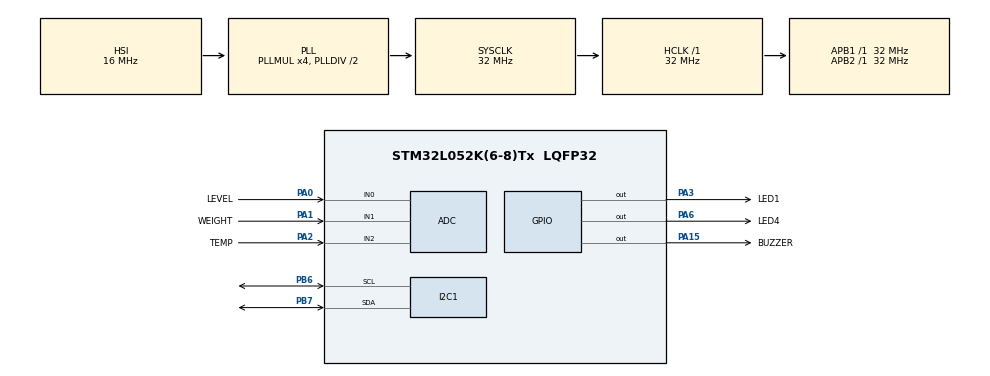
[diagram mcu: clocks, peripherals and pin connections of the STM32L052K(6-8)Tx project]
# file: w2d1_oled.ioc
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ADC.DMAContinuousRequests=ENABLE
ADC.SamplingTime=ADC_SAMPLETIME_160CYCLES_5
Dma.ADC.0.Direction=DMA_PERIPH_TO_MEMORY
Dma.ADC.0.Instance=DMA1_Channel1
Dma.ADC.0.MemDataAlignment=DMA_MDATAALIGN_WORD
Dma.ADC.0.MemInc=DMA_MINC_ENABLE
Dma.ADC.0.Mode=DMA_CIRCULAR
Dma.ADC.0.PeriphDataAlignment=DMA_PDATAALIGN_HALFWORD
Dma.ADC.0.PeriphInc=DMA_PINC_DISABLE
Dma.ADC.0.Priority=DMA_PRIORITY_LOW
Dma.Request0=ADC
I2C1.Timing=0x00707CBB
Mcu.Family=STM32L0
Mcu.Name=STM32L052K(6-8)Tx
Mcu.Package=LQFP32
NVIC.ADC1_COMP_IRQn=true\:0\:0\:false\:false\:true\:true\:true
NVIC.DMA1_Channel1_IRQn=true\:0\:0\:false\:false\:true\:false\:true
PA0.GPIO_Label=LEVEL
PA0.Signal=SharedAnalog_PA0
PA1.GPIO_Label=WEIGHT
PA1.Mode=IN1
PA1.Signal=ADC_IN1
PA13.Mode=Serial_Wire
PA13.Signal=SYS_SWDIO
PA14.Mode=Serial_Wire
PA14.Signal=SYS_SWCLK
PA15.GPIO_Label=BUZZER
PA15.Signal=GPIO_Output
PA2.GPIO_Label=TEMP
PA2.Mode=IN2
PA2.Signal=ADC_IN2
PA3.GPIO_Label=LED1
PA3.Signal=GPIO_Output
PA6.GPIO_Label=LED4
PA6.Signal=GPIO_Output
PB6.Mode=I2C
PB6.Signal=I2C1_SCL
PB7.Mode=I2C
PB7.Signal=I2C1_SDA
ProjectManager.HeapSize=0x200
ProjectManager.StackSize=0x400
ProjectManager.TargetToolchain=STM32CubeIDE
RCC.AHBFreq_Value=32000000
RCC.APB1Freq_Value=32000000
RCC.APB1TimFreq_Value=32000000
RCC.APB2Freq_Value=32000000
RCC.APB2TimFreq_Value=32000000
RCC.HCLKFreq_Value=32000000
RCC.HSI16_VALUE=16000000
RCC.HSI48_VALUE=48000000
RCC.HSI_VALUE=16000000
RCC.LSE_VALUE=32768
RCC.MSI_VALUE=2097000
RCC.PLLMUL=RCC_PLLMUL_4
RCC.SYSCLKFreq_VALUE=32000000
RCC.SYSCLKSource=RCC_SYSCLKSOURCE_PLLCLK
RCC.VCOOutputFreq_Value=64000000
SH.SharedAnalog_PA0.0=GPIO_Analog
SH.SharedAnalog_PA0.1=ADC_IN0,IN0
board=custom

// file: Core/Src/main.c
/* USER CODE BEGIN Header */
/**
 ******************************************************************************
 * @file           : main.c
 * @brief          : Main program body
 ******************************************************************************
 * @attention
 *
 * Copyright (c) 2021 STMicroelectronics.
 * All rights reserved.
 *
 * This software is licensed under terms that can be found in the LICENSE file
 * in the root directory of this software component.
 * If no LICENSE file comes with this software, it is provided AS-IS.
 *
 ******************************************************************************
 */
/* USER CODE END Header */
#include "main.h"

/* USER CODE BEGIN Includes */
#include "App.h"
/* USER CODE END Includes */

ADC_HandleTypeDef hadc;
DMA_HandleTypeDef hdma_adc;

I2C_HandleTypeDef hi2c1;

void SystemClock_Config(void);
static void MX_GPIO_Init(void);
static void MX_I2C1_Init(void);
static void MX_DMA_Init(void);
static void MX_ADC_Init(void);

int main(void)
{

  /* MCU Configuration--------------------------------------------------------*/

  /* Reset of all peripherals, Initializes the Flash interface and the Systick. */
  HAL_Init();

  /* Configure the system clock */
  SystemClock_Config();

  /* Initialize all configured peripherals */
  MX_GPIO_Init();
  MX_I2C1_Init();
  MX_DMA_Init();
  MX_ADC_Init();
  /* USER CODE BEGIN 2 */
  lcd_init(&hi2c1);
  OLED_ShowString(0, 0, "Starting...", 0);
  HAL_Delay(1000);
  OLED_Clear();
  /* USER CODE END 2 */

  /* Infinite loop */
  /* USER CODE BEGIN WHILE */
	while (1) {
		appLoop();
    /* USER CODE END WHILE */

	}
}

void SystemClock_Config(void)
{
  RCC_OscInitTypeDef RCC_OscInitStruct = {0};
  RCC_ClkInitTypeDef RCC_ClkInitStruct = {0};
  RCC_PeriphCLKInitTypeDef PeriphClkInit = {0};

  /** Configure the main internal regulator output voltage
  */
  __HAL_PWR_VOLTAGESCALING_CONFIG(PWR_REGULATOR_VOLTAGE_SCALE1);
  /** Initializes the RCC Oscillators according to the specified parameters
  * in the RCC_OscInitTypeDef structure.
  */
  RCC_OscInitStruct.OscillatorType = RCC_OSCILLATORTYPE_HSI;
  RCC_OscInitStruct.HSIState = RCC_HSI_ON;
  RCC_OscInitStruct.HSICalibrationValue = RCC_HSICALIBRATION_DEFAULT;
  RCC_OscInitStruct.PLL.PLLState = RCC_PLL_ON;
  RCC_OscInitStruct.PLL.PLLSource = RCC_PLLSOURCE_HSI;
  RCC_OscInitStruct.PLL.PLLMUL = RCC_PLLMUL_4;
  RCC_OscInitStruct.PLL.PLLDIV = RCC_PLLDIV_2;
  if (HAL_RCC_OscConfig(&RCC_OscInitStruct) != HAL_OK)
  {
    Error_Handler();
  }
  /** Initializes the CPU, AHB and APB buses clocks
  */
  RCC_ClkInitStruct.ClockType = RCC_CLOCKTYPE_HCLK|RCC_CLOCKTYPE_SYSCLK
                              |RCC_CLOCKTYPE_PCLK1|RCC_CLOCKTYPE_PCLK2;
  RCC_ClkInitStruct.SYSCLKSource = RCC_SYSCLKSOURCE_PLLCLK;
  RCC_ClkInitStruct.AHBCLKDivider = RCC_SYSCLK_DIV1;
  RCC_ClkInitStruct.APB1CLKDivider = RCC_HCLK_DIV1;
  RCC_ClkInitStruct.APB2CLKDivider = RCC_HCLK_DIV1;

  if (HAL_RCC_ClockConfig(&RCC_ClkInitStruct, FLASH_LATENCY_1) != HAL_OK)
  {
    Error_Handler();
  }
  PeriphClkInit.PeriphClockSelection = RCC_PERIPHCLK_I2C1;
  PeriphClkInit.I2c1ClockSelection = RCC_I2C1CLKSOURCE_PCLK1;
  if (HAL_RCCEx_PeriphCLKConfig(&PeriphClkInit) != HAL_OK)
  {
    Error_Handler();
  }
}

static void MX_ADC_Init(void)
{

  ADC_ChannelConfTypeDef sConfig = {0};

  /** Configure the global features of the ADC (Clock, Resolution, Data Alignment and number of conversion)
  */
  hadc.Instance = ADC1;
  hadc.Init.OversamplingMode = DISABLE;
  hadc.Init.ClockPrescaler = ADC_CLOCK_SYNC_PCLK_DIV2;
  hadc.Init.Resolution = ADC_RESOLUTION_12B;
  hadc.Init.SamplingTime = ADC_SAMPLETIME_160CYCLES_5;
  hadc.Init.ScanConvMode = ADC_SCAN_DIRECTION_FORWARD;
  hadc.Init.DataAlign = ADC_DATAALIGN_RIGHT;
  hadc.Init.ContinuousConvMode = DISABLE;
  hadc.Init.DiscontinuousConvMode = DISABLE;
  hadc.Init.ExternalTrigConvEdge = ADC_EXTERNALTRIGCONVEDGE_NONE;
  hadc.Init.ExternalTrigConv = ADC_SOFTWARE_START;
  hadc.Init.DMAContinuousRequests = ENABLE;
  hadc.Init.EOCSelection = ADC_EOC_SINGLE_CONV;
  hadc.Init.Overrun = ADC_OVR_DATA_PRESERVED;
  hadc.Init.LowPowerAutoWait = DISABLE;
  hadc.Init.LowPowerFrequencyMode = DISABLE;
  hadc.Init.LowPowerAutoPowerOff = DISABLE;
  if (HAL_ADC_Init(&hadc) != HAL_OK)
  {
    Error_Handler();
  }
  /** Configure for the selected ADC regular channel to be converted.
  */
  sConfig.Channel = ADC_CHANNEL_0;
  sConfig.Rank = ADC_RANK_CHANNEL_NUMBER;
  if (HAL_ADC_ConfigChannel(&hadc, &sConfig) != HAL_OK)
  {
    Error_Handler();
  }
  /** Configure for the selected ADC regular channel to be converted.
  */
  sConfig.Channel = ADC_CHANNEL_1;
  if (HAL_ADC_ConfigChannel(&hadc, &sConfig) != HAL_OK)
  {
    Error_Handler();
  }
  /** Configure for the selected ADC regular channel to be converted.
  */
  sConfig.Channel = ADC_CHANNEL_2;
  if (HAL_ADC_ConfigChannel(&hadc, &sConfig) != HAL_OK)
  {
    Error_Handler();
  }

}

static void MX_I2C1_Init(void)
{

  hi2c1.Instance = I2C1;
  hi2c1.Init.Timing = 0x00707CBB;
  hi2c1.Init.OwnAddress1 = 0;
  hi2c1.Init.AddressingMode = I2C_ADDRESSINGMODE_7BIT;
  hi2c1.Init.DualAddressMode = I2C_DUALADDRESS_DISABLE;
  hi2c1.Init.OwnAddress2 = 0;
  hi2c1.Init.OwnAddress2Masks = I2C_OA2_NOMASK;
  hi2c1.Init.GeneralCallMode = I2C_GENERALCALL_DISABLE;
  hi2c1.Init.NoStretchMode = I2C_NOSTRETCH_DISABLE;
  if (HAL_I2C_Init(&hi2c1) != HAL_OK)
  {
    Error_Handler();
  }
  /** Configure Analogue filter
  */
  if (HAL_I2CEx_ConfigAnalogFilter(&hi2c1, I2C_ANALOGFILTER_ENABLE) != HAL_OK)
  {
    Error_Handler();
  }
  /** Configure Digital filter
  */
  if (HAL_I2CEx_ConfigDigitalFilter(&hi2c1, 0) != HAL_OK)
  {
    Error_Handler();
  }

}

static void MX_DMA_Init(void)
{

  /* DMA controller clock enable */
  __HAL_RCC_DMA1_CLK_ENABLE();

  /* DMA interrupt init */
  /* DMA1_Channel1_IRQn interrupt configuration */
  HAL_NVIC_SetPriority(DMA1_Channel1_IRQn, 0, 0);
  HAL_NVIC_EnableIRQ(DMA1_Channel1_IRQn);

}

static void MX_GPIO_Init(void)
{
  GPIO_InitTypeDef GPIO_InitStruct = {0};

  /* GPIO Ports Clock Enable */
  __HAL_RCC_GPIOA_CLK_ENABLE();
  __HAL_RCC_GPIOB_CLK_ENABLE();

  /*Configure GPIO pin Output Level */
  HAL_GPIO_WritePin(GPIOA, LED1_Pin|LED4_Pin|BUZZER_Pin, GPIO_PIN_RESET);

  /*Configure GPIO pins : LED1_Pin LED4_Pin BUZZER_Pin */
  GPIO_InitStruct.Pin = LED1_Pin|LED4_Pin|BUZZER_Pin;
  GPIO_InitStruct.Mode = GPIO_MODE_OUTPUT_PP;
  GPIO_InitStruct.Pull = GPIO_NOPULL;
  GPIO_InitStruct.Speed = GPIO_SPEED_FREQ_LOW;
  HAL_GPIO_Init(GPIOA, &GPIO_InitStruct);

}

void Error_Handler(void)
{
	__disable_irq();
	while (1) {
	}
}
